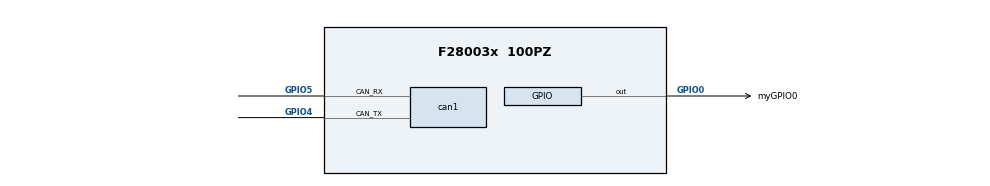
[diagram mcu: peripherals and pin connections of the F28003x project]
/**
 * @cliArgs --device "F28003x" --package "100PZ" --part "F28003x_100PZ" --context "system" --product "C2000WARE@5.01.00.00"
 * @versions {"tool":"1.18.0+3266"}
 */

/**
 * Import the modules used in this configuration.
 */
const adc              = scripting.addModule("/driverlib/adc.js", {}, false);
const adc1             = adc.addInstance();
const analog           = scripting.addModule("/driverlib/analog.js", {}, false);
const analog1          = analog.addInstance();
const asysctl          = scripting.addModule("/driverlib/asysctl.js");
const can              = scripting.addModule("/driverlib/can.js", {}, false);
const can1             = can.addInstance();
const gpio             = scripting.addModule("/driverlib/gpio.js", {}, false);
const gpio1            = gpio.addInstance();
const inputxbar_input  = scripting.addModule("/driverlib/inputxbar_input.js", {}, false);
const inputxbar_input1 = inputxbar_input.addInstance();

/**
 * Write custom configuration values to the imported modules.
 */
adc1.adcClockPrescaler  = "ADC_CLK_DIV_2_0";
adc1.soc0Trigger        = "ADC_TRIGGER_GPIO";
adc1.soc0SampleWindow   = 9;
adc1.soc1Trigger        = "ADC_TRIGGER_GPIO";
adc1.soc1SampleWindow   = 9;
adc1.soc2Trigger        = "ADC_TRIGGER_GPIO";
adc1.soc2SampleWindow   = 9;
adc1.soc2Channel        = "ADC_CH_ADCIN14";
adc1.soc1Channel        = "ADC_CH_ADCIN3";
adc1.soc0Channel        = "ADC_CH_ADCIN2";
adc1.$name              = "ADC0";
adc1.interruptPulseMode = "ADC_PULSE_END_OF_CONV";
adc1.enabledInts        = ["ADC_INT_NUMBER1"];
adc1.enableInterrupt1   = true;
adc1.enabledSOCs        = ["ADC_SOC_NUMBER0","ADC_SOC_NUMBER1","ADC_SOC_NUMBER2","ADC_SOC_NUMBER3"];
adc1.soc3Channel        = "ADC_CH_ADCIN11";
adc1.soc3SampleWindow   = 9;
adc1.soc3Trigger        = "ADC_TRIGGER_GPIO";

analog1.$name            = "myANALOGPinMux0";
adc1.analog              = analog1;
analog1.useCase          = "CUSTOM";
analog1.useInterfacePins = ["A11/B10/C0","A14/B14/C4","A2/B6/C9","A3, C7/B9"];

asysctl.analogReference        = "INTERNAL";
asysctl.analogReferenceVoltage = "1P65";

can1.$name                 = "can0";
can1.bitRate               = "1000000";
can1.can.$assign           = "CANA";
can1.can.can_rxPin.$assign = "GPIO5";
can1.can.can_txPin.$assign = "GPIO4";

gpio1.$name             = "myGPIO0";
gpio1.direction         = "GPIO_DIR_MODE_OUT";
gpio1.writeInitialValue = true;
gpio1.gpioPin.$assign   = "GPIO0";

inputxbar_input1.$name          = "myINPUTXBARINPUT0";
inputxbar_input1.inputxbarInput = "XBAR_INPUT5";
inputxbar_input1.inputxbarGpio  = "GPIO0";

/**
 * Pinmux solution for unlocked pins/peripherals. This ensures that minor changes to the automatic solver in a future
 * version of the tool will not impact the pinmux you originally saw.  These lines can be completely deleted in order to
 * re-solve from scratch.
 */
analog1.analog.$suggestSolution                  = "ANALOG";
analog1.analog["a11/b10/c0Pin"].$suggestSolution = "A11/B10/C0";
analog1.analog["a14/b14/c4Pin"].$suggestSolution = "A14/B14/C4";
analog1.analog["a2/b6/c9Pin"].$suggestSolution   = "A2/B6/C9";
analog1.analog["a3, c7/b9Pin"].$suggestSolution  = "A3, C7/B9";
